# MIK32 register map
Vendor: Mikron; Series: MIK32; File version: 1.0
Registers are 32-bit, read-write, reset 0x0 unless marked. A register's access mark holds for its fields unless they carry their own. Offsets are from the block's base; [hi:lo] are bit positions; {n}, {i} and the like mark numbered series; 'fields as' and 'values as' point back to an identical list.

## TIMER32_0 — регистры модуля таймера_0
Base 0x00050800
0x00 VALUE
  [31:0] TIM_VAL ro — текущее значение счетчика
0x04 TOP reset 0xFFFFFFFF — максимальное значение счетной последовательности
  [31:0] TIM_TOP — максимальное значение счетчика (ограничивает счетную последоваельность сверху)
0x08 PRESCALE — значение делителя
  [31:0] TIM_PRESCALE — Значение предварительного делителя. Предделитель вырабатывает тактовый сигнал для счета, частота которого в целое раз меньше входной
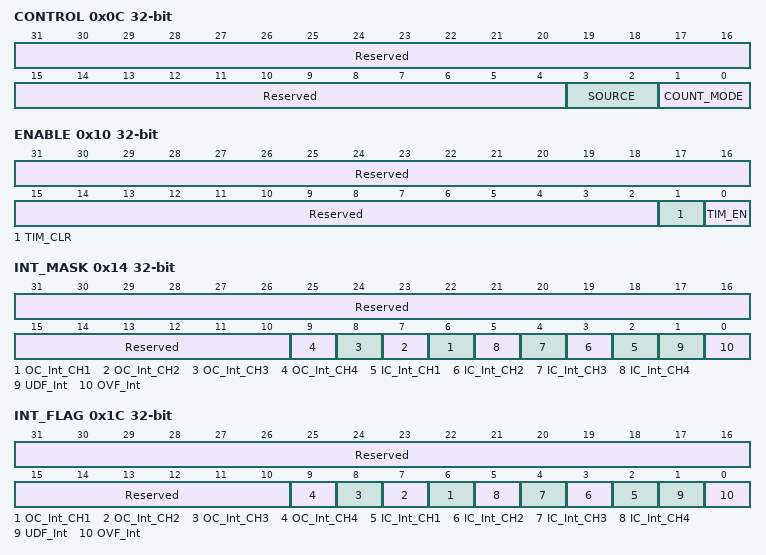
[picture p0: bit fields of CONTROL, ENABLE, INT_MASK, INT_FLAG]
0x0C CONTROL reset not defined — Конфигурационный регистр основного таймера
  [31:4] Reserved — Зарезервировано
  [3:2] SOURCE — Выбор источника тактового сигнала для счёта
    0=PRESCALER (Выход предделителя); 1=TIM1 (Вход модуля TIM1); 2=TX_PIN (Внешний вход TX); 3=TIM2 (Вход модуля TIM2)
  [1:0] COUNT_MODE — Режим счёта таймера
    0=Direct (Прямой режим); 1=Reverse (Обратный режим); 2=Bidirectional (Двунаправленный режим)
0x10 ENABLE — Регистр включения таймера
  [31:2] Reserved — Зарезервировано
  [1] TIM_CLR write-once — Сброс (обнуление) текущего значения счетчика при записи «1»
  [0] TIM_EN — Запуск/остановка работы счетчика
    0=Disable (Счетчик выключен); 1=Enable (Счетчик работает)
0x14 INT_MASK — Регистр маски прерываний
  [31:10] Reserved — Зарезервировано
  [n+5] OC_Int_CH{n} (n=1..4) — Маска прерывания совпадения {n} канала таймера
  [n+1] IC_Int_CH{n} (n=1..4) — Маска прерывания захвата {n} канала таймера
  [1] UDF_Int — Маска прерывания опустошения счетчика
  [0] OVF_Int — Маска прерывания по переполнению счетчика
0x18 INT_CLEAR reset 0xFFFFFFFF — Регистр сброса флагов прерываний
0x1C INT_FLAG — Регистр флагов прерываний
  [31:10] Reserved — Зарезервировано
  [n+5] OC_Int_CH{n} ro (n=1..4) — Статус прерывания совпадения {n} канала таймера
  [n+1] IC_Int_CH{n} ro (n=1..4) — Статус прерывания захвата {n} канала таймера
  [1] UDF_Int ro — Статус прерывания опустошения счетчика
  [0] OVF_Int ro — Статус прерывания по переполнению счетчика

## PVD_VCC — Управление монитором напряжения VCC
Base 0x00051800
0x00 DPF_VALUE reset 0x5DC — Настройка цифрового фильтра
  [31:14] Reserved — Зарезервировано
  [15:0] DPF — Коэффициент, определяющий длительность отфильтровываемых импульсов (на системной частоте)
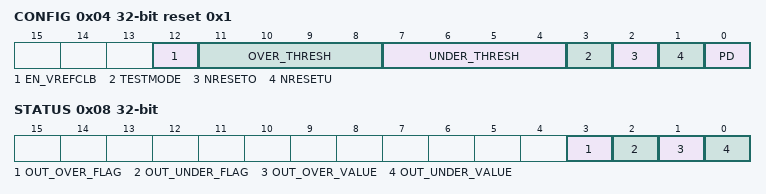
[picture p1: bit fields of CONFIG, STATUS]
0x04 CONFIG reset 0x1 — Регистр настроек
  [12] EN_VREFCLB — Использование в качестве опорного источника напряжения каллибруемый ОИН
  [11:8] OVER_THRESH — Верхний порог срабатывания монитора
  [7:4] UNDER_THRESH — Нижний порог срабатывания монитора
  [3] TESTMODE — Переход в тестовый режим
  [2] NRESETO — Отключение (сброс) детектирования вехнего порога
    0=Reset (Детектирование не выполняется, схема в состоянии сброса); 1=Normal (Нормальная работа)
  [1] NRESETU — Отключение (сброс) детектирования нижнего порога
    values as NRESETO
  [0] PD — Управление питанием монитора
    0=Enable (Монитор включен); 1=Disable (Монитор выключен)
0x08 STATUS ro — Регистр статуса
  [3] OUT_OVER_FLAG — Текущее состояние линии монитора верхнего порога с учетом цифровой фильтрации
  [2] OUT_UNDER_FLAG — Текущее состояние линии монитора нижнего порога с учетом цифровой фильтрации
  [1] OUT_OVER_VALUE — Текущее состояние линии монитора верхнего порога без цифровой фильтрации
  [0] OUT_UNDER_VALUE — Текущее состояние линии монитора нижнего порога без цифровой фильтрации

## PVD_AVCC — Управление монитором напряжения AVCC
Base 0x00085010
Registers as PVD_VCC; these are added or differ:
0x00 DPF_VALUE reset 0x5DC — Настройка цифрового фильтра
  [15:0] DPF — Коэффициент, определяющий длительность отфильтровываемых импульсов (на системной частоте)

## PAD_CONFIG — Модуль управления функцией ввода/вывода
Base 0x00050C00
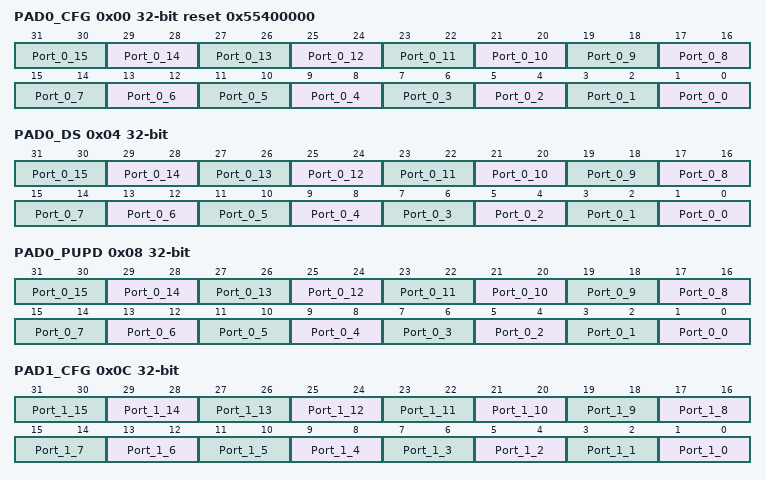
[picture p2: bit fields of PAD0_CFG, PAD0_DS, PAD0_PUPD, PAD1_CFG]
0x00 PAD0_CFG reset 0x55400000 — Управление функциями выводов PORT0
  [all] fields
    0=Func1_GPIO (Первая функция (порт общего назначения)); 1=Func2_interface (Вторая функция (последовательный интерфейс)); 2=Func3_interface_or_timer (Третья функция (последовательный интерфейс или таймер)); 3=Func4_Analog (Четвертая функция (аналоговый сигнал))
  [2n+1:2n] Port_0_{n} (n=0..15) — Значения двух бит кодируют выбранный функционал для вывода
0x04 PAD0_DS — Управление нагрузочной способностью выводов PORT0
  [all] fields
    0=2mA (Нагрузочная способность вывода 2мА); 1=4mA (Нагрузочная способность вывода 4мА); 0b1x=8mA (Нагрузочная способность вывода 8мА)
  [2n+1:2n] Port_0_{n} (n=0..15) — Значения двух бит кодируют выбранный режим для вывода
0x08 PAD0_PUPD — Управление резисторами подтяжки выводов PORT0
  [all] fields
    0=Pull_none (Без подтяжки); 1=Pull_up (Подтяжка к питанию); 2=Pull_down (Подтяжка к земле)
  [2n+1:2n] Port_0_{n} (n=0..15) — Значения двух бит кодируют выбранный режим для вывода
0x0C PAD1_CFG — Управление функциями выводов PORT1
  [all] fields
    values as the fields of PAD0_CFG
  [2n+1:2n] Port_1_{n} (n=0..15) — Значения двух бит кодируют выбранный функционал для вывода
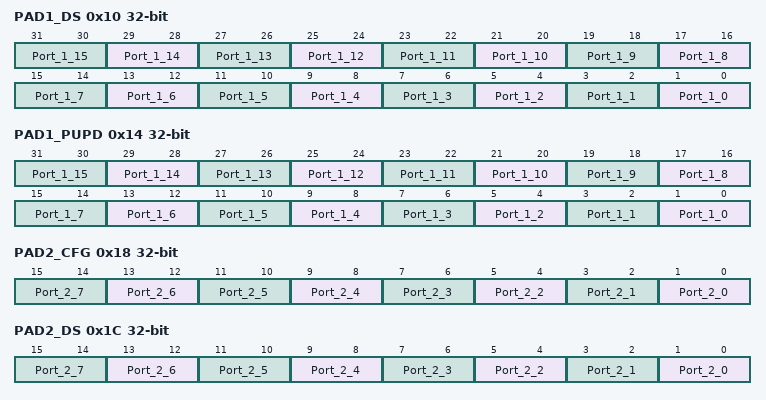
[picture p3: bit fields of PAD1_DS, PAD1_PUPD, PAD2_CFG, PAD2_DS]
0x10 PAD1_DS — Управление нагрузочной способностью выводов PORT1
  [all] fields
    values as the fields of PAD0_DS
  [2n+1:2n] Port_1_{n} (n=0..15) — Значения двух бит кодируют выбранный режим для вывода
0x14 PAD1_PUPD — Управление резисторами подтяжки выводов PORT1
  [all] fields
    values as the fields of PAD0_PUPD
  [2n+1:2n] Port_1_{n} (n=0..15) — Значения двух бит кодируют выбранный режим для вывода
0x18 PAD2_CFG — Управление функциями выводов PORT2
  [all] fields
    values as the fields of PAD0_CFG
  [2n+1:2n] Port_2_{n} (n=0..7) — Значения двух бит кодируют выбранный функционал для вывода
0x1C PAD2_DS — Управление нагрузочной способностью выводов PORT2
  [all] fields
    values as the fields of PAD0_DS
  [2n+1:2n] Port_2_{n} (n=0..7) — Значения двух бит кодируют выбранный режим для вывода
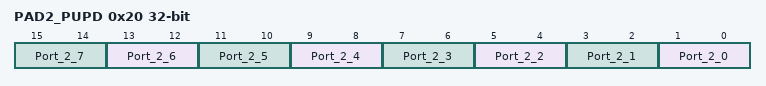
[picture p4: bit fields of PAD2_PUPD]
0x20 PAD2_PUPD — Управление резисторами подтяжки выводов PORT2
  [all] fields
    values as the fields of PAD0_PUPD
  [2n+1:2n] Port_2_{n} (n=0..7) — Значения двух бит кодируют выбранный режим для вывода

## Notices in the file
MIT License
Copyright (c) 2024 Лаборатория системных разработок, Mikron
Permission is hereby granted, free of charge, to any person obtaining a copy
of this software and associated documentation files (the "Software"), to deal
in the Software without restriction, including without limitation the rights
to use, copy, modify, merge, publish, distribute, sublicense, and/or sell
copies of the Software, and to permit persons to whom the Software is
furnished to do so, subject to the following conditions:
The above copyright notice and this permission notice shall be included in all
copies or substantial portions of the Software.
THE SOFTWARE IS PROVIDED "AS IS", WITHOUT WARRANTY OF ANY KIND, EXPRESS OR
IMPLIED, INCLUDING BUT NOT LIMITED TO THE WARRANTIES OF MERCHANTABILITY,
FITNESS FOR A PARTICULAR PURPOSE AND NONINFRINGEMENT. IN NO EVENT SHALL THE
AUTHORS OR COPYRIGHT HOLDERS BE LIABLE FOR ANY CLAIM, DAMAGES OR OTHER
LIABILITY, WHETHER IN AN ACTION OF CONTRACT, TORT OR OTHERWISE, ARISING FROM,
OUT OF OR IN CONNECTION WITH THE SOFTWARE OR THE USE OR OTHER DEALINGS IN THE
SOFTWARE.
